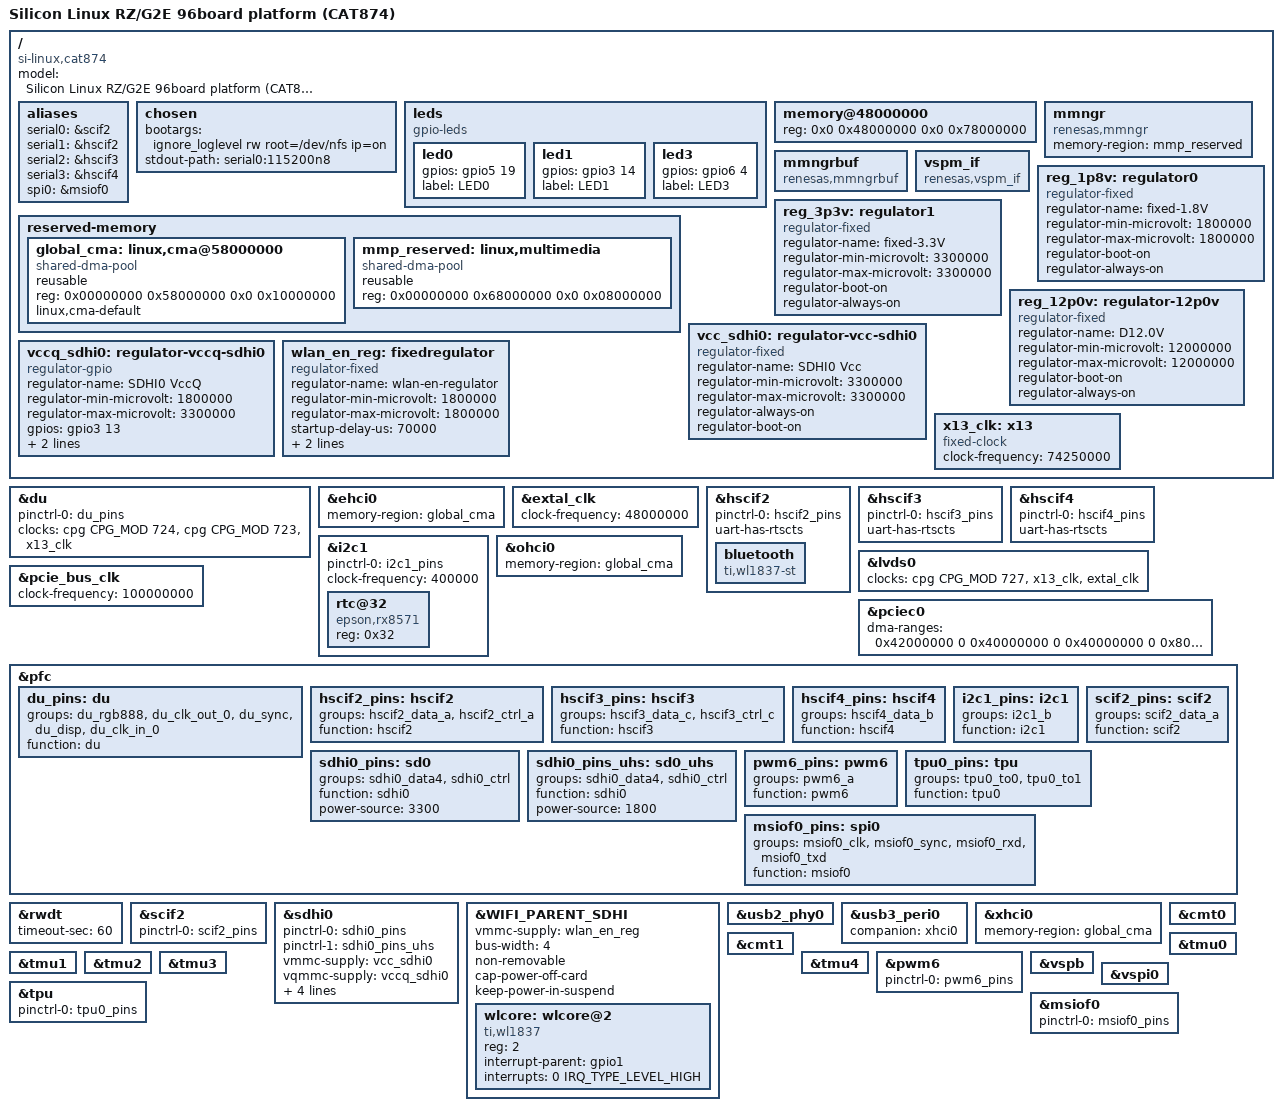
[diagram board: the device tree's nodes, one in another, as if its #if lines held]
// SPDX-License-Identifier: GPL-2.0
/*
 * Device Tree Source for the Silicon Linux RZ/G2E 96board platform (CAT874)
 * Rev.[A,B,C,D,E] common parts.
 *
 * Copyright (C) 2020 Renesas Electronics Corp.
 */

#include <dt-bindings/gpio/gpio.h>

/ {
	model = "Silicon Linux RZ/G2E 96board platform (CAT874)";
	compatible = "si-linux,cat874", "renesas,r8a774c0";

	aliases {
		serial0 = &scif2;
		serial1 = &hscif2;
		serial2 = &hscif3;
		serial3 = &hscif4;
		spi0 = &msiof0;
	};

	chosen {
		bootargs = "ignore_loglevel rw root=/dev/nfs ip=on";
		stdout-path = "serial0:115200n8";
	};

	leds {
		compatible = "gpio-leds";

		led0 {
			gpios = <&gpio5 19 GPIO_ACTIVE_HIGH>;
			label = "LED0";
		};

		led1 {
			gpios = <&gpio3 14 GPIO_ACTIVE_HIGH>;
			label = "LED1";
		};

		led3 {
			gpios = <&gpio6 4 GPIO_ACTIVE_HIGH>;
			label = "LED3";
		};
	};

	memory@48000000 {
		device_type = "memory";
		/* first 128MB is reserved for secure area. */
		reg = <0x0 0x48000000 0x0 0x78000000>;
	};

	reserved-memory {
		#address-cells = <2>;
		#size-cells = <2>;
		ranges;

		/* global autoconfigured region for contiguous allocations */
		global_cma: linux,cma@58000000 {
			compatible = "shared-dma-pool";
			reusable;
			reg = <0x00000000 0x58000000 0x0 0x10000000>;
			linux,cma-default;
		};

		/* device specific region for contiguous allocations */
		mmp_reserved: linux,multimedia {
			compatible = "shared-dma-pool";
			reusable;
			reg = <0x00000000 0x68000000 0x0 0x08000000>;
		};
	};

	mmngr {
		compatible = "renesas,mmngr";
		memory-region = <&mmp_reserved>;
	};

	mmngrbuf {
		compatible = "renesas,mmngrbuf";
	};

	vspm_if {
		compatible = "renesas,vspm_if";
	};

	reg_1p8v: regulator0 {
		compatible = "regulator-fixed";
		regulator-name = "fixed-1.8V";
		regulator-min-microvolt = <1800000>;
		regulator-max-microvolt = <1800000>;
		regulator-boot-on;
		regulator-always-on;
	};

	reg_3p3v: regulator1 {
		compatible = "regulator-fixed";
		regulator-name = "fixed-3.3V";
		regulator-min-microvolt = <3300000>;
		regulator-max-microvolt = <3300000>;
		regulator-boot-on;
		regulator-always-on;
	};

	reg_12p0v: regulator-12p0v {
		compatible = "regulator-fixed";
		regulator-name = "D12.0V";
		regulator-min-microvolt = <12000000>;
		regulator-max-microvolt = <12000000>;
		regulator-boot-on;
		regulator-always-on;
	};

	vcc_sdhi0: regulator-vcc-sdhi0 {
		compatible = "regulator-fixed";

		regulator-name = "SDHI0 Vcc";
		regulator-min-microvolt = <3300000>;
		regulator-max-microvolt = <3300000>;
		regulator-always-on;
		regulator-boot-on;
	};

	vccq_sdhi0: regulator-vccq-sdhi0 {
		compatible = "regulator-gpio";

		regulator-name = "SDHI0 VccQ";
		regulator-min-microvolt = <1800000>;
		regulator-max-microvolt = <3300000>;

		gpios = <&gpio3 13 GPIO_ACTIVE_HIGH>;
		gpios-states = <1>;
		states = <3300000 1
			  1800000 0>;
	};

	wlan_en_reg: fixedregulator {
		compatible = "regulator-fixed";
		regulator-name = "wlan-en-regulator";
		regulator-min-microvolt = <1800000>;
		regulator-max-microvolt = <1800000>;
		startup-delay-us = <70000>;

		gpio = <&gpio2 25 GPIO_ACTIVE_HIGH>;
		enable-active-high;
	};

	x13_clk: x13 {
		compatible = "fixed-clock";
		#clock-cells = <0>;
		clock-frequency = <74250000>;
	};
};

&du {
	pinctrl-0 = <&du_pins>;
	pinctrl-names = "default";
	status = "okay";

	clocks = <&cpg CPG_MOD 724>,
		 <&cpg CPG_MOD 723>,
		 <&x13_clk>;
	clock-names = "du.0", "du.1", "dclkin.0";
};

&ehci0 {
	status = "okay";

	memory-region = <&global_cma>;
};

&extal_clk {
	clock-frequency = <48000000>;
};

&hscif2 {
	pinctrl-0 = <&hscif2_pins>;
	pinctrl-names = "default";

	uart-has-rtscts;
	status = "okay";

	bluetooth {
		compatible = "ti,wl1837-st";
	};
};

&hscif3 {
	pinctrl-0 = <&hscif3_pins>;
	pinctrl-names = "default";

	uart-has-rtscts;
	status = "okay";
};

&hscif4 {
	pinctrl-0 = <&hscif4_pins>;
	pinctrl-names = "default";

	uart-has-rtscts;
	status = "okay";
};

&i2c1 {
	pinctrl-0 = <&i2c1_pins>;
	pinctrl-names = "default";

	status = "okay";
	clock-frequency = <400000>;

	rtc@32 {
		compatible = "epson,rx8571";
		reg = <0x32>;
	};
};

&lvds0 {
	status = "okay";

	clocks = <&cpg CPG_MOD 727>, <&x13_clk>, <&extal_clk>;
	clock-names = "fck", "dclkin.0", "extal";
};

&ohci0 {
	status = "okay";

	memory-region = <&global_cma>;
};

&pcie_bus_clk {
	clock-frequency = <100000000>;
};

&pciec0 {
	/* Map all possible DDR as inbound ranges */
	dma-ranges = <0x42000000 0 0x40000000 0 0x40000000 0 0x80000000>;
};

&pfc {
	du_pins: du {
		groups = "du_rgb888", "du_clk_out_0", "du_sync", "du_disp",
			 "du_clk_in_0";
		function = "du";
	};

	hscif2_pins: hscif2 {
		groups = "hscif2_data_a", "hscif2_ctrl_a";
		function = "hscif2";
	};

	hscif3_pins: hscif3 {
		groups = "hscif3_data_c", "hscif3_ctrl_c";
		function = "hscif3";
	};

	hscif4_pins: hscif4 {
		groups = "hscif4_data_b";
		function = "hscif4";
	};

	i2c1_pins: i2c1 {
		groups = "i2c1_b";
		function = "i2c1";
	};

	scif2_pins: scif2 {
		groups = "scif2_data_a";
		function = "scif2";
	};

	sdhi0_pins: sd0 {
		groups = "sdhi0_data4", "sdhi0_ctrl";
		function = "sdhi0";
		power-source = <3300>;
	};

	sdhi0_pins_uhs: sd0_uhs {
		groups = "sdhi0_data4", "sdhi0_ctrl";
		function = "sdhi0";
		power-source = <1800>;
	};

	pwm6_pins: pwm6 {
		groups = "pwm6_a";
		function = "pwm6";
	};

	tpu0_pins: tpu {
		groups = "tpu0_to0", "tpu0_to1";
		function = "tpu0";
	};

	msiof0_pins: spi0 {
		groups = "msiof0_clk", "msiof0_sync",
			 "msiof0_rxd", "msiof0_txd";
		function = "msiof0";
	};
};

&rwdt {
	timeout-sec = <60>;
	status = "okay";
};

&scif2 {
	pinctrl-0 = <&scif2_pins>;
	pinctrl-names = "default";

	status = "okay";
};

&sdhi0 {
	pinctrl-0 = <&sdhi0_pins>;
	pinctrl-1 = <&sdhi0_pins_uhs>;
	pinctrl-names = "default", "state_uhs";

	vmmc-supply = <&vcc_sdhi0>;
	vqmmc-supply = <&vccq_sdhi0>;
	cd-gpios = <&gpio3 12 GPIO_ACTIVE_LOW>;
	bus-width = <4>;
	sd-uhs-sdr50;
	sd-uhs-sdr104;
	status = "okay";
};

#ifdef WIFI_PARENT_SDHI
&WIFI_PARENT_SDHI {
	status = "okay";

	vmmc-supply = <&wlan_en_reg>;
	bus-width = <4>;
	non-removable;
	cap-power-off-card;
	keep-power-in-suspend;

	#address-cells = <1>;
	#size-cells = <0>;
	wlcore: wlcore@2 {
		compatible = "ti,wl1837";
		reg = <2>;
		interrupt-parent = <&gpio1>;
		interrupts = <0 IRQ_TYPE_LEVEL_HIGH>;
	};
};
#endif

&usb2_phy0 {
	status = "okay";
};

&usb3_peri0 {
	companion = <&xhci0>;
	status = "okay";
};

&xhci0 {
	status = "okay";

	memory-region = <&global_cma>;
};

&cmt0 {
	status = "okay";
};

&cmt1 {
	status = "okay";
};

&tmu0 {
	status = "okay";
};

&tmu1 {
	status = "okay";
};

&tmu2 {
	status = "okay";
};

&tmu3 {
	status = "okay";
};

&tmu4 {
	status = "okay";
};

&pwm6 {
	pinctrl-0 = <&pwm6_pins>;
	pinctrl-names = "default";

	status = "okay";
};

&vspb {
	status = "okay";
};

&vspi0 {
	status = "okay";
};

&tpu{
	pinctrl-0 = <&tpu0_pins>;
	pinctrl-names = "default";

	status = "okay";
};

&msiof0 {
	pinctrl-0 = <&msiof0_pins>;
	pinctrl-names = "default";

	status = "okay";
};
